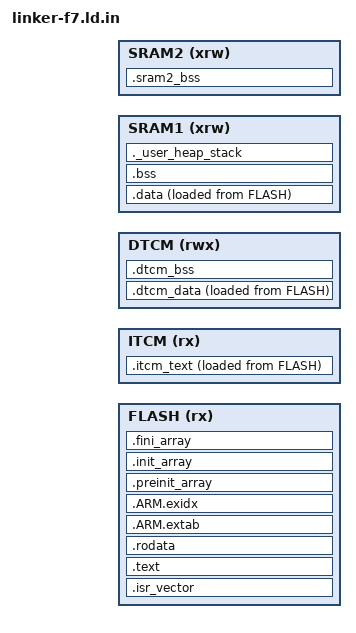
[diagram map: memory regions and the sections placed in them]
/* ============================================================
 *  Unified safe STM32F7 linker script (FLASH + ITCM + DTCM + SRAM1 + SRAM2)
 *  - ITCM: from CMake (@ITCM_ORIGIN@/@ITCM_LENGTH@)
 *  - DTCM: from map (@DTCM_LENGTH@)
 *  - SRAM2: fixed 16KB (0x4000) or override via @SRAM2_LENGTH@
 *  - SRAM1: computed by CMake (@SRAM1_ORIGIN@/@SRAM1_LENGTH@)
 *  Compatible with STM32CubeMX / CMSIS startup code
 * ============================================================ */

ENTRY(Reset_Handler)

/* ============================================================
 *  Memory layout (filled by CMake)
 * ============================================================ */
MEMORY
{
  FLASH (rx)  : ORIGIN = @FLASH_ORIGIN@,  LENGTH = @FLASH_LENGTH@

  /* Instruction TCM (CPU only) */
  ITCM  (rx)  : ORIGIN = @ITCM_ORIGIN@,   LENGTH = @ITCM_LENGTH@

  /* Data TCM (fast data, limited DMA visibility) */
  DTCM  (rwx) : ORIGIN = @DTCM_ORIGIN@,   LENGTH = @DTCM_LENGTH@

  /* System SRAM split */
  SRAM1 (xrw) : ORIGIN = @SRAM1_ORIGIN@,  LENGTH = @SRAM1_LENGTH@
  SRAM2 (xrw) : ORIGIN = @SRAM2_ORIGIN@,  LENGTH = @SRAM2_LENGTH@   /* typically 0x4000 */
}

/* ============================================================
 *  Heap & stack (safe default: SRAM1)
 * ============================================================ */
_Min_Heap_Size  = @HEAP_SIZE@;
_Min_Stack_Size = @STACK_SIZE@;

/* End of stack in SRAM1 */
_estack = ORIGIN(SRAM1) + LENGTH(SRAM1);

/* ============================================================
 *  Sections
 * ============================================================ */
SECTIONS
{
  /* ----------------------------------------------------------
   *  Vector table in FLASH
   * ---------------------------------------------------------- */
  .isr_vector :
  {
    . = ALIGN(4);
    KEEP(*(.isr_vector))
    . = ALIGN(4);
  } > FLASH

  /* ----------------------------------------------------------
   *  Program code in FLASH (default)
   * ---------------------------------------------------------- */
  .text :
  {
    . = ALIGN(4);

    *(.text)
    *(.text*)
    *(.glue_7)
    *(.glue_7t)
    *(.eh_frame)

    KEEP(*(.init))
    KEEP(*(.fini))

    . = ALIGN(4);
  } > FLASH

  /* ----------------------------------------------------------
   *  Read-only data
   * ---------------------------------------------------------- */
  .rodata :
  {
    . = ALIGN(4);
    *(.rodata)
    *(.rodata*)
    . = ALIGN(4);
  } > FLASH

  /* ----------------------------------------------------------
   *  ARM exception tables (C++)
   * ---------------------------------------------------------- */
  .ARM.extab :
  {
    . = ALIGN(4);
    *(.ARM.extab* .gnu.linkonce.armextab.*)
    . = ALIGN(4);
  } > FLASH

  .ARM.exidx :
  {
    . = ALIGN(4);
    __exidx_start = .;
    *(.ARM.exidx*)
    __exidx_end = .;
    . = ALIGN(4);
  } > FLASH

  /* ----------------------------------------------------------
   *  C++ ctors/dtors
   * ---------------------------------------------------------- */
  .preinit_array :
  {
    . = ALIGN(4);
    PROVIDE_HIDDEN(__preinit_array_start = .);
    KEEP(*(.preinit_array*))
    PROVIDE_HIDDEN(__preinit_array_end = .);
    . = ALIGN(4);
  } > FLASH

  .init_array :
  {
    . = ALIGN(4);
    PROVIDE_HIDDEN(__init_array_start = .);
    KEEP(*(SORT(.init_array.*)))
    KEEP(*(.init_array*))
    PROVIDE_HIDDEN(__init_array_end = .);
    . = ALIGN(4);
  } > FLASH

  .fini_array :
  {
    . = ALIGN(4);
    PROVIDE_HIDDEN(__fini_array_start = .);
    KEEP(*(SORT(.fini_array.*)))
    KEEP(*(.fini_array*))
    PROVIDE_HIDDEN(__fini_array_end = .);
    . = ALIGN(4);
  } > FLASH

  /* End of FLASH resident area */
  . = ALIGN(4);
  _etext = .;

  /* ----------------------------------------------------------
   *  Explicit ITCM code (opt-in)
   *  Use: __attribute__((section(".itcm_text")))
   *  Note: must be copied by startup if used.
   * ---------------------------------------------------------- */
  .itcm_text :
  {
    . = ALIGN(4);
    __itcm_text_start__ = .;

    *(.itcm_text)
    *(.itcm_text*)

    . = ALIGN(4);
    __itcm_text_end__ = .;
  } > ITCM AT > FLASH
  _siitcm = LOADADDR(.itcm_text);

  /* ----------------------------------------------------------
   *  Initialized data in SRAM1 (safe DMA-visible default)
   * ---------------------------------------------------------- */
  .data :
  {
    . = ALIGN(4);
    _sdata = .;
    __data_start__ = _sdata;

    *(.data)
    *(.data*)
    *(.RamFunc)
    *(.RamFunc*)

    . = ALIGN(4);
    _edata = .;
    __data_end__ = _edata;
  } > SRAM1 AT > FLASH
  _sidata = LOADADDR(.data);

  /* ----------------------------------------------------------
   *  Explicit initialized fast data in DTCM (opt-in)
   *  Use: __attribute__((section(".dtcm_data")))
   *  Note: must be copied by startup if used.
   * ---------------------------------------------------------- */
  .dtcm_data :
  {
    . = ALIGN(4);
    __dtcm_data_start__ = .;

    *(.dtcm_data)
    *(.dtcm_data*)

    . = ALIGN(4);
    __dtcm_data_end__ = .;
  } > DTCM AT > FLASH
  _sidtcm = LOADADDR(.dtcm_data);

  /* ----------------------------------------------------------
   *  Uninitialized data in SRAM1
   * ---------------------------------------------------------- */
  .bss :
  {
    . = ALIGN(4);
    _sbss = .;
    __bss_start__ = _sbss;

    *(.bss)
    *(.bss*)
    *(COMMON)

    . = ALIGN(4);
    _ebss = .;
    __bss_end__ = _ebss;
  } > SRAM1

  /* ----------------------------------------------------------
   *  Explicit uninitialized fast data in DTCM (opt-in)
   *  Use: __attribute__((section(".dtcm_bss")))
   * ---------------------------------------------------------- */
  .dtcm_bss (NOLOAD) :
  {
    . = ALIGN(4);
    __dtcm_bss_start__ = .;

    *(.dtcm_bss)
    *(.dtcm_bss*)

    . = ALIGN(4);
    __dtcm_bss_end__ = .;
  } > DTCM

  /* ----------------------------------------------------------
   *  Optional SRAM2 region usage (opt-in)
   *  Use: __attribute__((section(".sram2_bss")))
   * ---------------------------------------------------------- */
  .sram2_bss (NOLOAD) :
  {
    . = ALIGN(4);
    __sram2_bss_start__ = .;

    *(.sram2_bss)
    *(.sram2_bss*)

    . = ALIGN(4);
    __sram2_bss_end__ = .;
  } > SRAM2

  /* ----------------------------------------------------------
   *  Heap and stack in SRAM1
   * ---------------------------------------------------------- */
  ._user_heap_stack :
  {
    . = ALIGN(8);
    PROVIDE(end = .);
    PROVIDE(_end = .);

    . = . + _Min_Heap_Size;
    . = . + _Min_Stack_Size;

    . = ALIGN(8);
  } > SRAM1

  /* ----------------------------------------------------------
   *  Discard unused standard libraries
   * ---------------------------------------------------------- */
  /DISCARD/ :
  {
    libc.a ( * )
    libm.a ( * )
    libgcc.a ( * )
  }

  .ARM.attributes 0 : { *(.ARM.attributes) }
}
